VERSION ""

NS_ :

BS_:

BU_: VESC1 VESC2 VESC3 VESC4 VESC5 VESC6 VESC7 VESC8 Main_ECU

BO_ 3221225472 VECTOR__INDEPENDENT_SIG_MSG: 0 Vector__XXX
 SG_ TorqueValue : 7|8@0+ (1,0) [0|0] "V" Vector__XXX
 SG_ TorqueValue : 9|10@0+ (1,0) [0|0] "" Vector__XXX
 SG_ TorqueValue : 7|8@0+ (1,0) [0|0] "" Vector__XXX
 SG_ TorqueValue : 15|16@0+ (1,0) [0|0] "" Vector__XXX

BO_ 2147486728 VESC_Command_AbsHBrakeCurrent_V8: 8 Main_ECU
 SG_ Command_HBrakeCurrent_V8 : 7|32@0- (0.001,0) [-2147483.648|2147483.647] "mA"  VESC8

BO_ 2147486727 VESC_Command_AbsHBrakeCurrent_V7: 8 Main_ECU
 SG_ Command_HBrakeCurrent_V7 : 7|32@0- (0.001,0) [-2147483.648|2147483.647] "mA"  VESC7

BO_ 2147486726 VESC_Command_AbsHBrakeCurrent_V6: 8 Main_ECU
 SG_ Command_HBrakeCurrent_V6 : 7|32@0- (0.001,0) [-2147483.648|2147483.647] "mA"  VESC6

BO_ 2147486725 VESC_Command_AbsHBrakeCurrent_V5: 8 Main_ECU
 SG_ Command_HBrakeCurrent_V5 : 7|32@0- (0.001,0) [-2147483.648|2147483.647] "mA"  VESC5

BO_ 2147486724 VESC_Command_AbsHBrakeCurrent_V4: 8 Main_ECU
 SG_ Command_HBrakeCurrent_V4 : 7|32@0- (0.001,0) [-2147483.648|2147483.647] "mA"  VESC4

BO_ 2147486723 VESC_Command_AbsHBrakeCurrent_V3: 8 Main_ECU
 SG_ Command_HBrakeCurrent_V3 : 7|32@0- (0.001,0) [-2147483.648|2147483.647] "mA"  VESC3

BO_ 2147486722 VESC_Command_AbsHBrakeCurrent_V2: 8 Main_ECU
 SG_ Command_HBrakeCurrent_V2 : 7|32@0- (0.001,0) [-2147483.648|2147483.647] "mA"  VESC2

BO_ 2147486721 VESC_Command_AbsHBrakeCurrent_V1: 8 Main_ECU
 SG_ Command_HBrakeCurrent_V1 : 7|32@0- (0.001,0) [-2147483.648|2147483.647] "mA"  VESC1

BO_ 2147486984 VESC_Command_RelHBrakeCurrent_V8: 8 Main_ECU
 SG_ Command_RelativeHBrakeCurrent_V8 : 7|32@0- (0.001,0) [-100|100] "%"  VESC8

BO_ 2147486983 VESC_Command_RelHBrakeCurrent_V7: 8 Main_ECU
 SG_ Command_RelativeHBrakeCurrent_V7 : 7|32@0- (0.001,0) [-100|100] "%"  VESC7

BO_ 2147486982 VESC_Command_RelHBrakeCurrent_V6: 8 Main_ECU
 SG_ Command_RelativeHBrakeCurrent_V6 : 7|32@0- (0.001,0) [-100|100] "%"  VESC6

BO_ 2147486981 VESC_Command_RelHBrakeCurrent_V5: 8 Main_ECU
 SG_ Command_RelativeHBrakeCurrent_V5 : 7|32@0- (0.001,0) [-100|100] "%"  VESC5

BO_ 2147486980 VESC_Command_RelHBrakeCurrent_V4: 8 Main_ECU
 SG_ Command_RelativeHBrakeCurrent_V4 : 7|32@0- (0.001,0) [-100|100] "%"  VESC4

BO_ 2147486979 VESC_Command_RelHBrakeCurrent_V3: 8 Main_ECU
 SG_ Command_RelativeHBrakeCurrent_V3 : 7|32@0- (0.001,0) [-100|100] "%"  VESC3

BO_ 2147486978 VESC_Command_RelHBrakeCurrent_V2: 8 Main_ECU
 SG_ Command_RelativeHBrakeCurrent_V2 : 7|32@0- (0.001,0) [-100|100] "%"  VESC2

BO_ 2147486977 VESC_Command_RelHBrakeCurrent_V1: 8 Main_ECU
 SG_ Command_RelativeHBrakeCurrent_V1 : 7|32@0- (0.001,0) [-100|100] "%"  VESC1

BO_ 2147489281 VESC_Set_CurrentLimitPerm_V1: 8 Main_ECU
 SG_ Setting_CurrentLimitMin_V1 : 7|32@0- (0.001,0) [-2147483.648|2147483.647] ""  VESC1
 SG_ Setting_CurrentLimitMax_V1 : 39|32@0- (0.001,0) [-2147483.648|2147483.647] ""  VESC1

BO_ 2147489025 VESC_Set_CurrentLimitTemp_V1: 8 Main_ECU
 SG_ Setting_CurrentLimitMin_V1 : 7|32@0- (0.001,0) [-2147483.648|2147483.647] ""  VESC1
 SG_ Setting_CurrentLimitMax_V1 : 39|32@0- (0.001,0) [-2147483.648|2147483.647] ""  VESC1

BO_ 2147486465 VESC_Command_RelBrakeCurrent_V1: 4 Main_ECU
 SG_ Command_RelativeBrakeCurrent_V1 : 7|32@0- (0.001,0) [-100|100] "%"  VESC1

BO_ 2147486209 VESC_Command_RelCurrent_V1: 4 Main_ECU
 SG_ Command_RelativeCurrent_V1 : 7|32@0- (0.001,0) [-100|100] "%"  VESC1

BO_ 2147484673 VESC_Command_POS_V1: 4 Main_ECU
 SG_ Command_POS_V1 : 7|32@0- (1,0) [-2147483648|2147483647] "RPM"  VESC1

BO_ 2147484161 VESC_Command_AbsBrakeCurrent_V1: 4 Main_ECU
 SG_ Command_BrakeCurrent_V1 : 7|32@0- (0.001,0) [-2147483.648|2147483.647] "mA"  VESC1

BO_ 2147483905 VESC_Command_AbsCurrent_V1: 4 Main_ECU
 SG_ Command_Current_V1 : 7|32@0- (0.001,0) [-2147483.648|2147483.647] "mA"  VESC1

BO_ 2147484417 VESC_Command_RPM_V1: 4 Main_ECU
 SG_ Command_RPM_V1 : 7|32@0- (1,0) [-2147483648|2147483647] "RPM"  VESC1

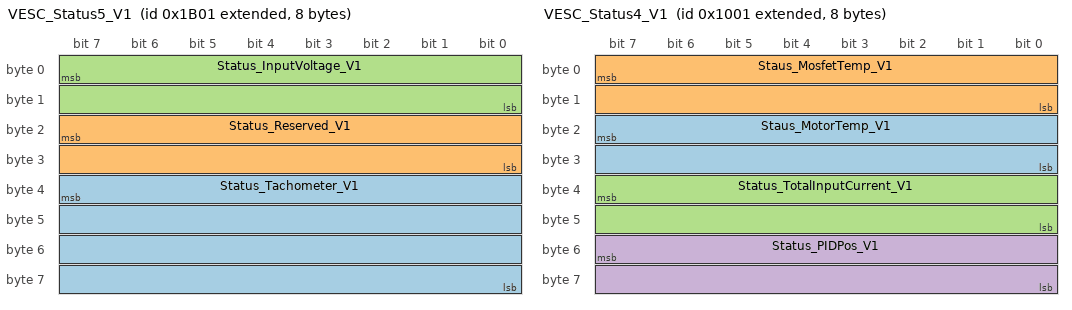
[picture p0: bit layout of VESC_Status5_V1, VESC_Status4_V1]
BO_ 2147490561 VESC_Status5_V1: 8 VESC1
 SG_ Status_Tachometer_V1 : 39|32@0- (1,0) [0|0] "RPM"  Main_ECU
 SG_ Status_Reserved_V1 : 23|16@0- (1,0) [0|0] ""  Main_ECU
 SG_ Status_InputVoltage_V1 : 7|16@0- (0.1,0) [0|0] ""  Main_ECU

BO_ 2147487745 VESC_Status4_V1: 8 VESC1
 SG_ Staus_MotorTemp_V1 : 23|16@0- (0.1,0) [-3276.8|3276.7] "°C"  Main_ECU
 SG_ Staus_MosfetTemp_V1 : 7|16@0- (0.1,0) [-3276.8|3276.7] "°C"  Main_ECU
 SG_ Status_TotalInputCurrent_V1 : 39|16@0- (0.1,0) [-3276.8|3276.7] "A"  Main_ECU
 SG_ Status_PIDPos_V1 : 55|16@0- (0.02,0) [-655.36|655.34] ""  Main_ECU

BO_ 2147487489 VESC_Status3_V1: 8 VESC1
 SG_ Status_WattHoursCharged_V1 : 39|32@0- (1e-05,0) [-21474.83648|21474.83647] "Wh"  Main_ECU
 SG_ Status_WattHours_V1 : 7|32@0- (1e-05,0) [-21474.83648|21474.83647] "Wh"  Main_ECU

BO_ 2147487233 VESC_Status2_V1: 8 VESC1
 SG_ Status_AmpHoursCharged_V1 : 39|32@0- (1e-05,0) [-21474.83648|21474.83647] "Ah"  Main_ECU
 SG_ Status_AmpHours_V1 : 7|32@0- (1e-05,0) [-21474.83648|21474.83647] "Ah"  Main_ECU

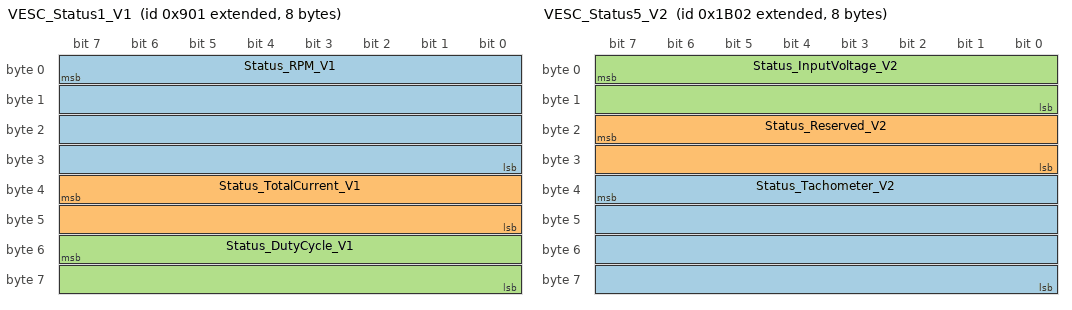
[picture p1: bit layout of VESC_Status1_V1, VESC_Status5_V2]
BO_ 2147485953 VESC_Status1_V1: 8 VESC1
 SG_ Status_RPM_V1 : 7|32@0- (1,0) [-2147483648|2147483647] "RPM"  Main_ECU
 SG_ Status_TotalCurrent_V1 : 39|16@0- (0.1,0) [-3276.8|3276.7] "A"  Main_ECU
 SG_ Status_DutyCycle_V1 : 55|16@0- (0.1,0) [-100|100] "%"  Main_ECU

BO_ 2147483649 VESC_Command_DutyCycle_V1: 4 Main_ECU
 SG_ Command_DutyCycle_V1 : 7|32@0- (0.001,0) [-100|100] "%"  VESC1

BO_ 2147489282 VESC_Set_CurrentLimitPerm_V2: 8 Main_ECU
 SG_ Setting_CurrentLimitMin_V2 : 7|32@0- (0.001,0) [-2147483.648|2147483.647] ""  VESC2
 SG_ Setting_CurrentLimitMax_V2 : 39|32@0- (0.001,0) [-2147483.648|2147483.647] ""  VESC2

BO_ 2147489026 VESC_Set_CurrentLimitTemp_V2: 8 Main_ECU
 SG_ Setting_CurrentLimitMin_V2 : 7|32@0- (0.001,0) [-2147483.648|2147483.647] ""  VESC2
 SG_ Setting_CurrentLimitMax_V2 : 39|32@0- (0.001,0) [-2147483.648|2147483.647] ""  VESC2

BO_ 2147486466 VESC_Command_RelBrakeCurrent_V2: 4 Main_ECU
 SG_ Command_RelativeBrakeCurrent_V2 : 7|32@0- (0.001,0) [-100|100] "%"  VESC2

BO_ 2147486210 VESC_Command_RelCurrent_V2: 4 Main_ECU
 SG_ Command_RelativeCurrent_V2 : 7|32@0- (0.001,0) [-100|100] "%"  VESC2

BO_ 2147484674 VESC_Command_POS_V2: 4 Main_ECU
 SG_ Command_POS_V2 : 7|32@0- (1,0) [-2147483648|2147483647] "RPM"  VESC2

BO_ 2147484162 VESC_Command_AbsBrakeCurrent_V2: 4 Main_ECU
 SG_ Command_BrakeCurrent_V2 : 7|32@0- (0.001,0) [-2147483.648|2147483.647] "mA"  VESC2

BO_ 2147483906 VESC_Command_AbsCurrent_V2: 4 Main_ECU
 SG_ Command_Current_V2 : 7|32@0- (0.001,0) [-2147483.648|2147483.647] "mA"  VESC2

BO_ 2147484418 VESC_Command_RPM_V2: 4 Main_ECU
 SG_ Command_RPM_V2 : 7|32@0- (1,0) [-2147483648|2147483647] "RPM"  VESC2

BO_ 2147490562 VESC_Status5_V2: 8 VESC2
 SG_ Status_Tachometer_V2 : 39|32@0- (1,0) [0|0] "RPM"  Main_ECU
 SG_ Status_Reserved_V2 : 23|16@0- (1,0) [0|0] ""  Main_ECU
 SG_ Status_InputVoltage_V2 : 7|16@0- (0.1,0) [0|0] ""  Main_ECU

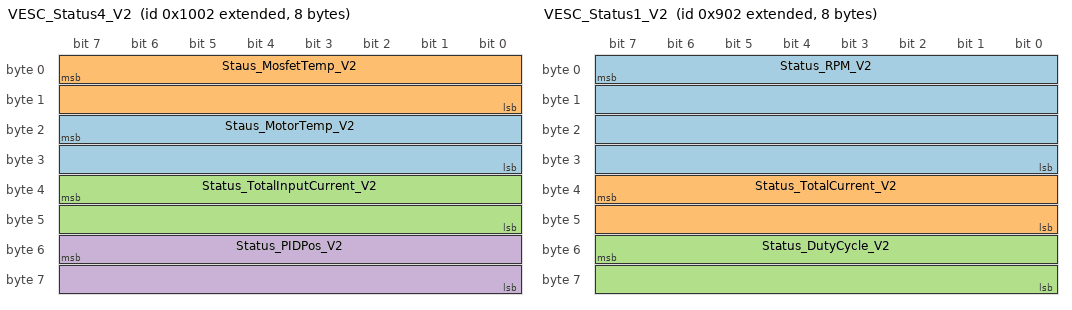
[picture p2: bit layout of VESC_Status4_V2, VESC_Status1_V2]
BO_ 2147487746 VESC_Status4_V2: 8 VESC2
 SG_ Staus_MotorTemp_V2 : 23|16@0- (0.1,0) [-3276.8|3276.7] "°C"  Main_ECU
 SG_ Staus_MosfetTemp_V2 : 7|16@0- (0.1,0) [-3276.8|3276.7] "°C"  Main_ECU
 SG_ Status_TotalInputCurrent_V2 : 39|16@0- (0.1,0) [-3276.8|3276.7] "A"  Main_ECU
 SG_ Status_PIDPos_V2 : 55|16@0- (0.02,0) [-655.36|655.34] ""  Main_ECU

BO_ 2147487490 VESC_Status3_V2: 8 VESC2
 SG_ Status_WattHoursCharged_V2 : 39|32@0- (1e-05,0) [-21474.83648|21474.83647] "Wh"  Main_ECU
 SG_ Status_WattHours_V2 : 7|32@0- (1e-05,0) [-21474.83648|21474.83647] "Wh"  Main_ECU

BO_ 2147487234 VESC_Status2_V2: 8 VESC2
 SG_ Status_AmpHoursCharged_V2 : 39|32@0- (1e-05,0) [-21474.83648|21474.83647] "Ah"  Main_ECU
 SG_ Status_AmpHours_V2 : 7|32@0- (1e-05,0) [-21474.83648|21474.83647] "Ah"  Main_ECU

BO_ 2147485954 VESC_Status1_V2: 8 VESC2
 SG_ Status_RPM_V2 : 7|32@0- (1,0) [-2147483648|2147483647] "RPM"  Main_ECU
 SG_ Status_TotalCurrent_V2 : 39|16@0- (0.1,0) [-3276.8|3276.7] "A"  Main_ECU
 SG_ Status_DutyCycle_V2 : 55|16@0- (0.1,0) [-100|100] "%"  Main_ECU

BO_ 2147483650 VESC_Command_DutyCycle_V2: 4 Main_ECU
 SG_ Command_DutyCycle_V2 : 7|32@0- (0.001,0) [-100|100] "%"  VESC2

BO_ 2147489283 VESC_Set_CurrentLimitPerm_V3: 8 Main_ECU
 SG_ Setting_CurrentLimitMin_V3 : 7|32@0- (0.001,0) [-2147483.648|2147483.647] ""  VESC3
 SG_ Setting_CurrentLimitMax_V3 : 39|32@0- (0.001,0) [-2147483.648|2147483.647] ""  VESC3

BO_ 2147489027 VESC_Set_CurrentLimitTemp_V3: 8 Main_ECU
 SG_ Setting_CurrentLimitMin_V3 : 7|32@0- (0.001,0) [-2147483.648|2147483.647] ""  VESC3
 SG_ Setting_CurrentLimitMax_V3 : 39|32@0- (0.001,0) [-2147483.648|2147483.647] ""  VESC3

BO_ 2147486467 VESC_Command_RelBrakeCurrent_V3: 4 Main_ECU
 SG_ Command_RelativeBrakeCurrent_V3 : 7|32@0- (0.001,0) [-100|100] "%"  VESC3

BO_ 2147486211 VESC_Command_RelCurrent_V3: 4 Main_ECU
 SG_ Command_RelativeCurrent_V3 : 7|32@0- (0.001,0) [-100|100] "%"  VESC3

BO_ 2147484675 VESC_Command_POS_V3: 4 Main_ECU
 SG_ Command_POS_V3 : 7|32@0- (1,0) [-2147483648|2147483647] "RPM"  VESC3

BO_ 2147484163 VESC_Command_AbsBrakeCurrent_V3: 4 Main_ECU
 SG_ Command_BrakeCurrent_V3 : 7|32@0- (0.001,0) [-2147483.648|2147483.647] "mA"  VESC3

BO_ 2147483907 VESC_Command_AbsCurrent_V3: 4 Main_ECU
 SG_ Command_Current_V3 : 7|32@0- (0.001,0) [-2147483.648|2147483.647] "mA"  VESC3

BO_ 2147484419 VESC_Command_RPM_V3: 4 Main_ECU
 SG_ Command_RPM_V3 : 7|32@0- (1,0) [-2147483648|2147483647] "RPM"  VESC3

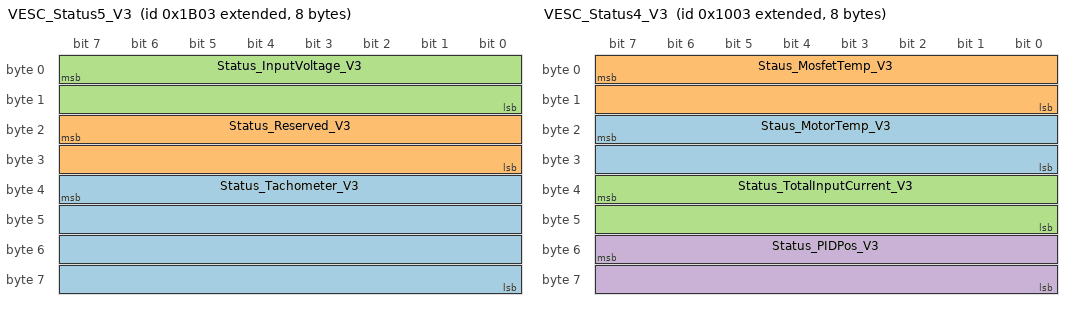
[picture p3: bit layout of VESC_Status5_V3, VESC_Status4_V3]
BO_ 2147490563 VESC_Status5_V3: 8 VESC3
 SG_ Status_Tachometer_V3 : 39|32@0- (1,0) [0|0] "RPM"  Main_ECU
 SG_ Status_Reserved_V3 : 23|16@0- (1,0) [0|0] ""  Main_ECU
 SG_ Status_InputVoltage_V3 : 7|16@0- (0.1,0) [0|0] ""  Main_ECU

BO_ 2147487747 VESC_Status4_V3: 8 VESC3
 SG_ Staus_MotorTemp_V3 : 23|16@0- (0.1,0) [-3276.8|3276.7] "°C"  Main_ECU
 SG_ Staus_MosfetTemp_V3 : 7|16@0- (0.1,0) [-3276.8|3276.7] "°C"  Main_ECU
 SG_ Status_TotalInputCurrent_V3 : 39|16@0- (0.1,0) [-3276.8|3276.7] "A"  Main_ECU
 SG_ Status_PIDPos_V3 : 55|16@0- (0.02,0) [-655.36|655.34] ""  Main_ECU

BO_ 2147487491 VESC_Status3_V3: 8 VESC3
 SG_ Status_WattHoursCharged_V3 : 39|32@0- (1e-05,0) [-21474.83648|21474.83647] "Wh"  Main_ECU
 SG_ Status_WattHours_V3 : 7|32@0- (1e-05,0) [-21474.83648|21474.83647] "Wh"  Main_ECU

BO_ 2147487235 VESC_Status2_V3: 8 VESC3
 SG_ Status_AmpHoursCharged_V3 : 39|32@0- (1e-05,0) [-21474.83648|21474.83647] "Ah"  Main_ECU
 SG_ Status_AmpHours_V3 : 7|32@0- (1e-05,0) [-21474.83648|21474.83647] "Ah"  Main_ECU

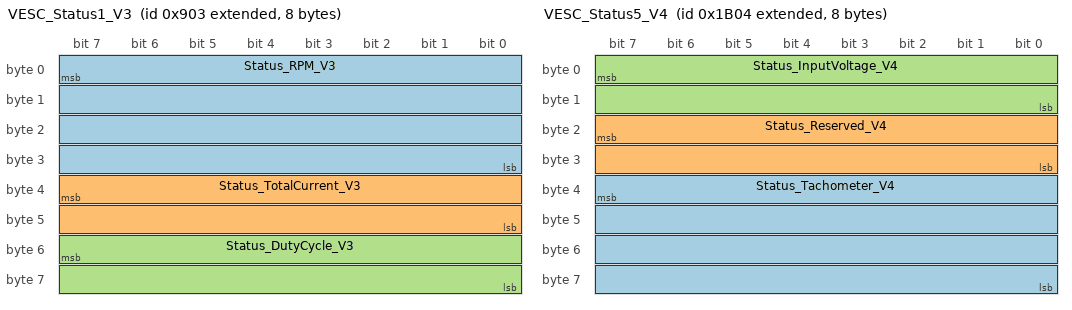
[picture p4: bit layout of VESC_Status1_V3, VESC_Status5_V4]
BO_ 2147485955 VESC_Status1_V3: 8 VESC3
 SG_ Status_RPM_V3 : 7|32@0- (1,0) [-2147483648|2147483647] "RPM"  Main_ECU
 SG_ Status_TotalCurrent_V3 : 39|16@0- (0.1,0) [-3276.8|3276.7] "A"  Main_ECU
 SG_ Status_DutyCycle_V3 : 55|16@0- (0.1,0) [-100|100] "%"  Main_ECU

BO_ 2147483651 VESC_Command_DutyCycle_V3: 4 Main_ECU
 SG_ Command_DutyCycle_V3 : 7|32@0- (0.001,0) [-100|100] "%"  VESC3

BO_ 2147489284 VESC_Set_CurrentLimitPerm_V4: 8 Main_ECU
 SG_ Setting_CurrentLimitMin_V4 : 7|32@0- (0.001,0) [-2147483.648|2147483.647] ""  VESC4
 SG_ Setting_CurrentLimitMax_V4 : 39|32@0- (0.001,0) [-2147483.648|2147483.647] ""  VESC4

BO_ 2147489028 VESC_Set_CurrentLimitTemp_V4: 8 Main_ECU
 SG_ Setting_CurrentLimitMin_V4 : 7|32@0- (0.001,0) [-2147483.648|2147483.647] ""  VESC4
 SG_ Setting_CurrentLimitMax_V4 : 39|32@0- (0.001,0) [-2147483.648|2147483.647] ""  VESC4

BO_ 2147486468 VESC_Command_RelBrakeCurrent_V4: 4 Main_ECU
 SG_ Command_RelativeBrakeCurrent_V4 : 7|32@0- (0.001,0) [-100|100] "%"  VESC4

BO_ 2147486212 VESC_Command_RelCurrent_V4: 4 Main_ECU
 SG_ Command_RelativeCurrent_V4 : 7|32@0- (0.001,0) [-100|100] "%"  VESC4

BO_ 2147484676 VESC_Command_POS_V4: 4 Main_ECU
 SG_ Command_POS_V4 : 7|32@0- (1,0) [-2147483648|2147483647] "RPM"  VESC4

BO_ 2147484164 VESC_Command_AbsBrakeCurrent_V4: 4 Main_ECU
 SG_ Command_BrakeCurrent_V4 : 7|32@0- (0.001,0) [-2147483.648|2147483.647] "mA"  VESC4

BO_ 2147483908 VESC_Command_AbsCurrent_V4: 4 Main_ECU
 SG_ Command_Current_V4 : 7|32@0- (0.001,0) [-2147483.648|2147483.647] "mA"  VESC4

BO_ 2147484420 VESC_Command_RPM_V4: 4 Main_ECU
 SG_ Command_RPM_V4 : 7|32@0- (1,0) [-2147483648|2147483647] "RPM"  VESC4

BO_ 2147490564 VESC_Status5_V4: 8 VESC4
 SG_ Status_Tachometer_V4 : 39|32@0- (1,0) [0|0] "RPM"  Main_ECU
 SG_ Status_Reserved_V4 : 23|16@0- (1,0) [0|0] ""  Main_ECU
 SG_ Status_InputVoltage_V4 : 7|16@0- (0.1,0) [0|0] ""  Main_ECU

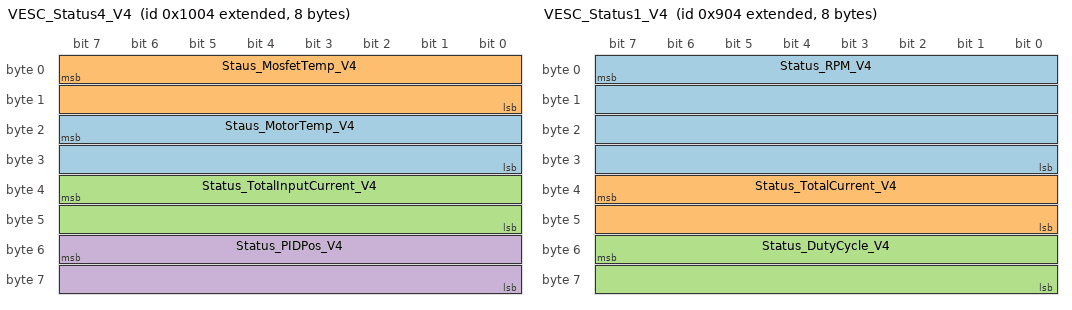
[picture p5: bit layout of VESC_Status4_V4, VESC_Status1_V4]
BO_ 2147487748 VESC_Status4_V4: 8 VESC4
 SG_ Staus_MotorTemp_V4 : 23|16@0- (0.1,0) [-3276.8|3276.7] "°C"  Main_ECU
 SG_ Staus_MosfetTemp_V4 : 7|16@0- (0.1,0) [-3276.8|3276.7] "°C"  Main_ECU
 SG_ Status_TotalInputCurrent_V4 : 39|16@0- (0.1,0) [-3276.8|3276.7] "A"  Main_ECU
 SG_ Status_PIDPos_V4 : 55|16@0- (0.02,0) [-655.36|655.34] ""  Main_ECU

BO_ 2147487492 VESC_Status3_V4: 8 VESC4
 SG_ Status_WattHoursCharged_V4 : 39|32@0- (1e-05,0) [-21474.83648|21474.83647] "Wh"  Main_ECU
 SG_ Status_WattHours_V4 : 7|32@0- (1e-05,0) [-21474.83648|21474.83647] "Wh"  Main_ECU

BO_ 2147487236 VESC_Status2_V4: 8 VESC4
 SG_ Status_AmpHoursCharged_V4 : 39|32@0- (1e-05,0) [-21474.83648|21474.83647] "Ah"  Main_ECU
 SG_ Status_AmpHours_V4 : 7|32@0- (1e-05,0) [-21474.83648|21474.83647] "Ah"  Main_ECU

BO_ 2147485956 VESC_Status1_V4: 8 VESC4
 SG_ Status_RPM_V4 : 7|32@0- (1,0) [-2147483648|2147483647] "RPM"  Main_ECU
 SG_ Status_TotalCurrent_V4 : 39|16@0- (0.1,0) [-3276.8|3276.7] "A"  Main_ECU
 SG_ Status_DutyCycle_V4 : 55|16@0- (0.1,0) [-100|100] "%"  Main_ECU

BO_ 2147483652 VESC_Command_DutyCycle_V4: 4 Main_ECU
 SG_ Command_DutyCycle_V4 : 7|32@0- (0.001,0) [-100|100] "%"  VESC4

BO_ 2147489285 VESC_Set_CurrentLimitPerm_V5: 8 Main_ECU
 SG_ Setting_CurrentLimitMin_V5 : 7|32@0- (0.001,0) [-2147483.648|2147483.647] ""  VESC5
 SG_ Setting_CurrentLimitMax_V5 : 39|32@0- (0.001,0) [-2147483.648|2147483.647] ""  VESC5

BO_ 2147489029 VESC_Set_CurrentLimitTemp_V5: 8 Main_ECU
 SG_ Setting_CurrentLimitMin_V5 : 7|32@0- (0.001,0) [-2147483.648|2147483.647] ""  VESC5
 SG_ Setting_CurrentLimitMax_V5 : 39|32@0- (0.001,0) [-2147483.648|2147483.647] ""  VESC5

BO_ 2147486469 VESC_Command_RelBrakeCurrent_V5: 4 Main_ECU
 SG_ Command_RelativeBrakeCurrent_V5 : 7|32@0- (0.001,0) [-100|100] "%"  VESC5

BO_ 2147486213 VESC_Command_RelCurrent_V5: 4 Main_ECU
 SG_ Command_RelativeCurrent_V5 : 7|32@0- (0.001,0) [-100|100] "%"  VESC5

BO_ 2147484677 VESC_Command_POS_V5: 4 Main_ECU
 SG_ Command_POS_V5 : 7|32@0- (1,0) [-2147483648|2147483647] "RPM"  VESC5

BO_ 2147484165 VESC_Command_AbsBrakeCurrent_V5: 4 Main_ECU
 SG_ Command_BrakeCurrent_V5 : 7|32@0- (0.001,0) [-2147483.648|2147483.647] "mA"  VESC5

BO_ 2147483909 VESC_Command_AbsCurrent_V5: 4 Main_ECU
 SG_ Command_Current_V5 : 7|32@0- (0.001,0) [-2147483.648|2147483.647] "mA"  VESC5

BO_ 2147484421 VESC_Command_RPM_V5: 4 Main_ECU
 SG_ Command_RPM_V5 : 7|32@0- (1,0) [-2147483648|2147483647] "RPM"  VESC5

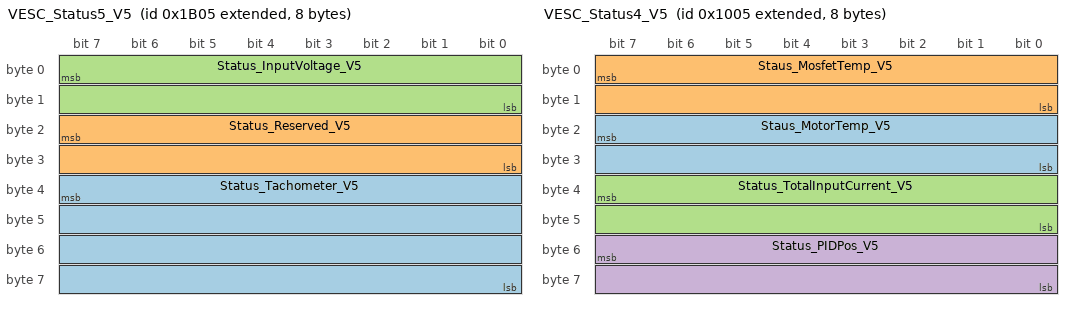
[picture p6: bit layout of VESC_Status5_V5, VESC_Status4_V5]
BO_ 2147490565 VESC_Status5_V5: 8 VESC5
 SG_ Status_Tachometer_V5 : 39|32@0- (1,0) [0|0] "RPM"  Main_ECU
 SG_ Status_Reserved_V5 : 23|16@0- (1,0) [0|0] ""  Main_ECU
 SG_ Status_InputVoltage_V5 : 7|16@0- (0.1,0) [0|0] ""  Main_ECU

BO_ 2147487749 VESC_Status4_V5: 8 VESC5
 SG_ Staus_MotorTemp_V5 : 23|16@0- (0.1,0) [-3276.8|3276.7] "°C"  Main_ECU
 SG_ Staus_MosfetTemp_V5 : 7|16@0- (0.1,0) [-3276.8|3276.7] "°C"  Main_ECU
 SG_ Status_TotalInputCurrent_V5 : 39|16@0- (0.1,0) [-3276.8|3276.7] "A"  Main_ECU
 SG_ Status_PIDPos_V5 : 55|16@0- (0.02,0) [-655.36|655.34] ""  Main_ECU

BO_ 2147487493 VESC_Status3_V5: 8 VESC5
 SG_ Status_WattHoursCharged_V5 : 39|32@0- (1e-05,0) [-21474.83648|21474.83647] "Wh"  Main_ECU
 SG_ Status_WattHours_V5 : 7|32@0- (1e-05,0) [-21474.83648|21474.83647] "Wh"  Main_ECU

BO_ 2147487237 VESC_Status2_V5: 8 VESC5
 SG_ Status_AmpHoursCharged_V5 : 39|32@0- (1e-05,0) [-21474.83648|21474.83647] "Ah"  Main_ECU
 SG_ Status_AmpHours_V5 : 7|32@0- (1e-05,0) [-21474.83648|21474.83647] "Ah"  Main_ECU

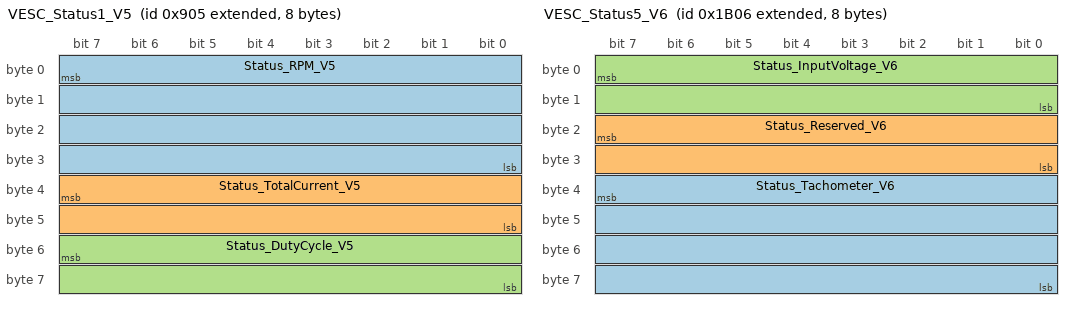
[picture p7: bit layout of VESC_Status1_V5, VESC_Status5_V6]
BO_ 2147485957 VESC_Status1_V5: 8 VESC5
 SG_ Status_RPM_V5 : 7|32@0- (1,0) [-2147483648|2147483647] "RPM"  Main_ECU
 SG_ Status_TotalCurrent_V5 : 39|16@0- (0.1,0) [-3276.8|3276.7] "A"  Main_ECU
 SG_ Status_DutyCycle_V5 : 55|16@0- (0.1,0) [-100|100] "%"  Main_ECU

BO_ 2147483653 VESC_Command_DutyCycle_V5: 4 Main_ECU
 SG_ Command_DutyCycle_V5 : 7|32@0- (0.001,0) [-100|100] "%"  VESC5

BO_ 2147489286 VESC_Set_CurrentLimitPerm_V6: 8 Main_ECU
 SG_ Setting_CurrentLimitMin_V6 : 7|32@0- (0.001,0) [-2147483.648|2147483.647] ""  VESC6
 SG_ Setting_CurrentLimitMax_V6 : 39|32@0- (0.001,0) [-2147483.648|2147483.647] ""  VESC6

BO_ 2147489030 VESC_Set_CurrentLimitTemp_V6: 8 Main_ECU
 SG_ Setting_CurrentLimitMin_V6 : 7|32@0- (0.001,0) [-2147483.648|2147483.647] ""  VESC6
 SG_ Setting_CurrentLimitMax_V6 : 39|32@0- (0.001,0) [-2147483.648|2147483.647] ""  VESC6

BO_ 2147486470 VESC_Command_RelBrakeCurrent_V6: 4 Main_ECU
 SG_ Command_RelativeBrakeCurrent_V6 : 7|32@0- (0.001,0) [-100|100] "%"  VESC6

BO_ 2147486214 VESC_Command_RelCurrent_V6: 4 Main_ECU
 SG_ Command_RelativeCurrent_V6 : 7|32@0- (0.001,0) [-100|100] "%"  VESC6

BO_ 2147484678 VESC_Command_POS_V6: 4 Main_ECU
 SG_ Command_POS_V6 : 7|32@0- (1,0) [-2147483648|2147483647] "RPM"  VESC6

BO_ 2147484166 VESC_Command_AbsBrakeCurrent_V6: 4 Main_ECU
 SG_ Command_BrakeCurrent_V6 : 7|32@0- (0.001,0) [-2147483.648|2147483.647] "mA"  VESC6

BO_ 2147483910 VESC_Command_AbsCurrent_V6: 4 Main_ECU
 SG_ Command_Current_V6 : 7|32@0- (0.001,0) [-2147483.648|2147483.647] "mA"  VESC6

BO_ 2147484422 VESC_Command_RPM_V6: 4 Main_ECU
 SG_ Command_RPM_V6 : 7|32@0- (1,0) [-2147483648|2147483647] "RPM"  VESC6

BO_ 2147490566 VESC_Status5_V6: 8 VESC6
 SG_ Status_Tachometer_V6 : 39|32@0- (1,0) [0|0] "RPM"  Main_ECU
 SG_ Status_Reserved_V6 : 23|16@0- (1,0) [0|0] ""  Main_ECU
 SG_ Status_InputVoltage_V6 : 7|16@0- (0.1,0) [0|0] ""  Main_ECU

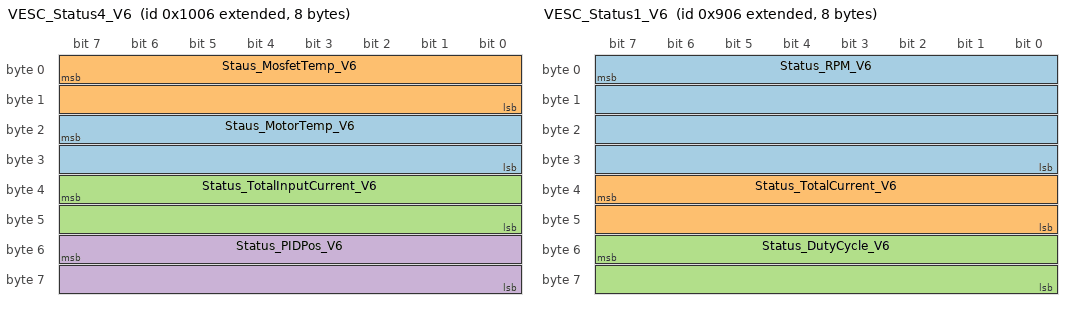
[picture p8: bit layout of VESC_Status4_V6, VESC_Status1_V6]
BO_ 2147487750 VESC_Status4_V6: 8 VESC6
 SG_ Staus_MotorTemp_V6 : 23|16@0- (0.1,0) [-3276.8|3276.7] "°C"  Main_ECU
 SG_ Staus_MosfetTemp_V6 : 7|16@0- (0.1,0) [-3276.8|3276.7] "°C"  Main_ECU
 SG_ Status_TotalInputCurrent_V6 : 39|16@0- (0.1,0) [-3276.8|3276.7] "A"  Main_ECU
 SG_ Status_PIDPos_V6 : 55|16@0- (0.02,0) [-655.36|655.34] ""  Main_ECU

BO_ 2147487494 VESC_Status3_V6: 8 VESC6
 SG_ Status_WattHoursCharged_V6 : 39|32@0- (1e-05,0) [-21474.83648|21474.83647] "Wh"  Main_ECU
 SG_ Status_WattHours_V6 : 7|32@0- (1e-05,0) [-21474.83648|21474.83647] "Wh"  Main_ECU

BO_ 2147487238 VESC_Status2_V6: 8 VESC6
 SG_ Status_AmpHoursCharged_V6 : 39|32@0- (1e-05,0) [-21474.83648|21474.83647] "Ah"  Main_ECU
 SG_ Status_AmpHours_V6 : 7|32@0- (1e-05,0) [-21474.83648|21474.83647] "Ah"  Main_ECU

BO_ 2147485958 VESC_Status1_V6: 8 VESC6
 SG_ Status_RPM_V6 : 7|32@0- (1,0) [-2147483648|2147483647] "RPM"  Main_ECU
 SG_ Status_TotalCurrent_V6 : 39|16@0- (0.1,0) [-3276.8|3276.7] "A"  Main_ECU
 SG_ Status_DutyCycle_V6 : 55|16@0- (0.1,0) [-100|100] "%"  Main_ECU

BO_ 2147483654 VESC_Command_DutyCycle_V6: 4 Main_ECU
 SG_ Command_DutyCycle_V6 : 7|32@0- (0.001,0) [-100|100] "%"  VESC6

BO_ 2147489287 VESC_Set_CurrentLimitPerm_V7: 8 Main_ECU
 SG_ Setting_CurrentLimitMin_V7 : 7|32@0- (0.001,0) [-2147483.648|2147483.647] ""  VESC7
 SG_ Setting_CurrentLimitMax_V7 : 39|32@0- (0.001,0) [-2147483.648|2147483.647] ""  VESC7

BO_ 2147489031 VESC_Set_CurrentLimitTemp_V7: 8 Main_ECU
 SG_ Setting_CurrentLimitMin_V7 : 7|32@0- (0.001,0) [-2147483.648|2147483.647] ""  VESC7
 SG_ Setting_CurrentLimitMax_V7 : 39|32@0- (0.001,0) [-2147483.648|2147483.647] ""  VESC7

BO_ 2147486471 VESC_Command_RelBrakeCurrent_V7: 4 Main_ECU
 SG_ Command_RelativeBrakeCurrent_V7 : 7|32@0- (0.001,0) [-100|100] "%"  VESC7

BO_ 2147486215 VESC_Command_RelCurrent_V7: 4 Main_ECU
 SG_ Command_RelativeCurrent_V7 : 7|32@0- (0.001,0) [-100|100] "%"  VESC7

BO_ 2147484679 VESC_Command_POS_V7: 4 Main_ECU
 SG_ Command_POS_V7 : 7|32@0- (1,0) [-2147483648|2147483647] "RPM"  VESC7

BO_ 2147484167 VESC_Command_AbsBrakeCurrent_V7: 4 Main_ECU
 SG_ Command_BrakeCurrent_V7 : 7|32@0- (0.001,0) [-2147483.648|2147483.647] "mA"  VESC7

BO_ 2147483911 VESC_Command_AbsCurrent_V7: 4 Main_ECU
 SG_ Command_Current_V7 : 7|32@0- (0.001,0) [-2147483.648|2147483.647] "mA"  VESC7

BO_ 2147484423 VESC_Command_RPM_V7: 4 Main_ECU
 SG_ Command_RPM_V7 : 7|32@0- (1,0) [-2147483648|2147483647] "RPM"  VESC7

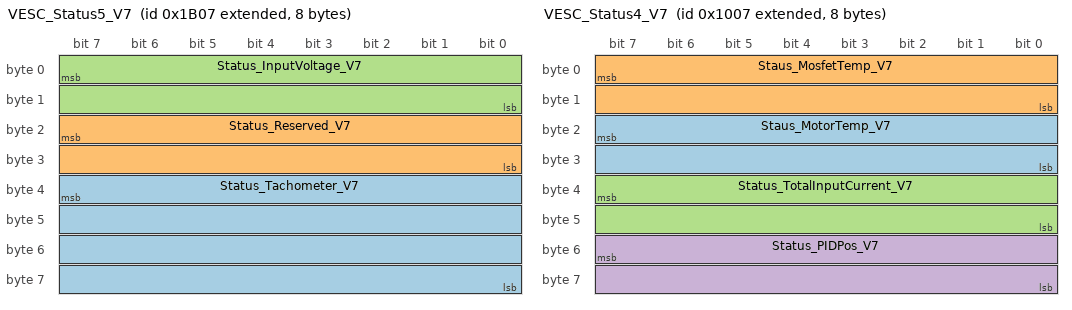
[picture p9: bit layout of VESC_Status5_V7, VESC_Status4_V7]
BO_ 2147490567 VESC_Status5_V7: 8 VESC7
 SG_ Status_Tachometer_V7 : 39|32@0- (1,0) [0|0] "RPM"  Main_ECU
 SG_ Status_Reserved_V7 : 23|16@0- (1,0) [0|0] ""  Main_ECU
 SG_ Status_InputVoltage_V7 : 7|16@0- (0.1,0) [0|0] ""  Main_ECU

BO_ 2147487751 VESC_Status4_V7: 8 VESC7
 SG_ Staus_MotorTemp_V7 : 23|16@0- (0.1,0) [-3276.8|3276.7] "°C"  Main_ECU
 SG_ Staus_MosfetTemp_V7 : 7|16@0- (0.1,0) [-3276.8|3276.7] "°C"  Main_ECU
 SG_ Status_TotalInputCurrent_V7 : 39|16@0- (0.1,0) [-3276.8|3276.7] "A"  Main_ECU
 SG_ Status_PIDPos_V7 : 55|16@0- (0.02,0) [-655.36|655.34] ""  Main_ECU

BO_ 2147487495 VESC_Status3_V7: 8 VESC7
 SG_ Status_WattHoursCharged_V7 : 39|32@0- (1e-05,0) [-21474.83648|21474.83647] "Wh"  Main_ECU
 SG_ Status_WattHours_V7 : 7|32@0- (1e-05,0) [-21474.83648|21474.83647] "Wh"  Main_ECU

BO_ 2147487239 VESC_Status2_V7: 8 VESC7
 SG_ Status_AmpHoursCharged_V7 : 39|32@0- (1e-05,0) [-21474.83648|21474.83647] "Ah"  Main_ECU
 SG_ Status_AmpHours_V7 : 7|32@0- (1e-05,0) [-21474.83648|21474.83647] "Ah"  Main_ECU

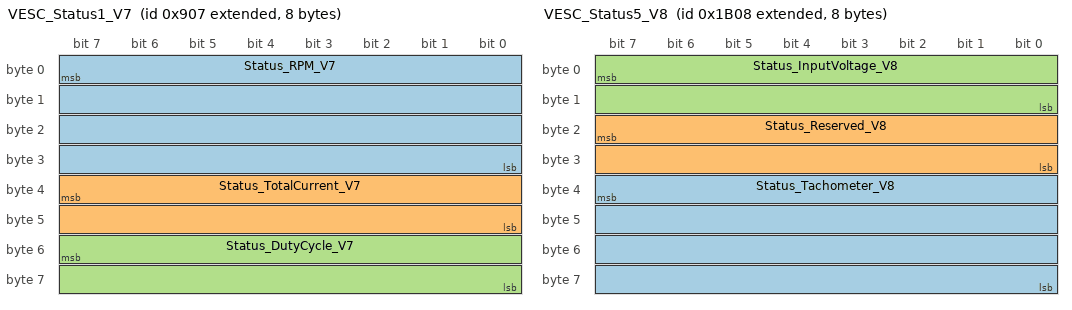
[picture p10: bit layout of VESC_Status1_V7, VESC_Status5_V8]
BO_ 2147485959 VESC_Status1_V7: 8 VESC7
 SG_ Status_RPM_V7 : 7|32@0- (1,0) [-2147483648|2147483647] "RPM"  Main_ECU
 SG_ Status_TotalCurrent_V7 : 39|16@0- (0.1,0) [-3276.8|3276.7] "A"  Main_ECU
 SG_ Status_DutyCycle_V7 : 55|16@0- (0.1,0) [-100|100] "%"  Main_ECU

BO_ 2147483655 VESC_Command_DutyCycle_V7: 4 Main_ECU
 SG_ Command_DutyCycle_V7 : 7|32@0- (0.001,0) [-100|100] "%"  VESC7

BO_ 2147489288 VESC_Set_CurrentLimitPerm_V8: 8 Main_ECU
 SG_ Setting_CurrentLimitMin_V8 : 7|32@0- (0.001,0) [-2147483.648|2147483.647] ""  VESC8
 SG_ Setting_CurrentLimitMax_V8 : 39|32@0- (0.001,0) [-2147483.648|2147483.647] ""  VESC8

BO_ 2147489032 VESC_Set_CurrentLimitTemp_V8: 8 Main_ECU
 SG_ Setting_CurrentLimitMin_V8 : 7|32@0- (0.001,0) [-2147483.648|2147483.647] ""  VESC8
 SG_ Setting_CurrentLimitMax_V8 : 39|32@0- (0.001,0) [-2147483.648|2147483.647] ""  VESC8

BO_ 2147486472 VESC_Command_RelBrakeCurrent_V8: 4 Main_ECU
 SG_ Command_RelativeBrakeCurrent_V8 : 7|32@0- (0.001,0) [-100|100] "%"  VESC8

BO_ 2147486216 VESC_Command_RelCurrent_V8: 4 Main_ECU
 SG_ Command_RelativeCurrent_V8 : 7|32@0- (0.001,0) [-100|100] "%"  VESC8

BO_ 2147484680 VESC_Command_POS_V8: 4 Main_ECU
 SG_ Command_POS_V8 : 7|32@0- (1,0) [-2147483648|2147483647] "RPM"  VESC8

BO_ 2147484168 VESC_Command_AbsBrakeCurrent_V8: 4 Main_ECU
 SG_ Command_BrakeCurrent_V8 : 7|32@0- (0.001,0) [-2147483.648|2147483.647] "mA"  VESC8

BO_ 2147483912 VESC_Command_AbsCurrent_V8: 4 Main_ECU
 SG_ Command_Current_V8 : 7|32@0- (0.001,0) [-2147483.648|2147483.647] "mA"  VESC8

BO_ 2147484424 VESC_Command_RPM_V8: 4 Main_ECU
 SG_ Command_RPM_V8 : 7|32@0- (1,0) [-2147483648|2147483647] "RPM"  VESC8

BO_ 2147490568 VESC_Status5_V8: 8 VESC8
 SG_ Status_Tachometer_V8 : 39|32@0- (1,0) [0|0] "RPM"  Main_ECU
 SG_ Status_Reserved_V8 : 23|16@0- (1,0) [0|0] ""  Main_ECU
 SG_ Status_InputVoltage_V8 : 7|16@0- (0.1,0) [0|0] ""  Main_ECU

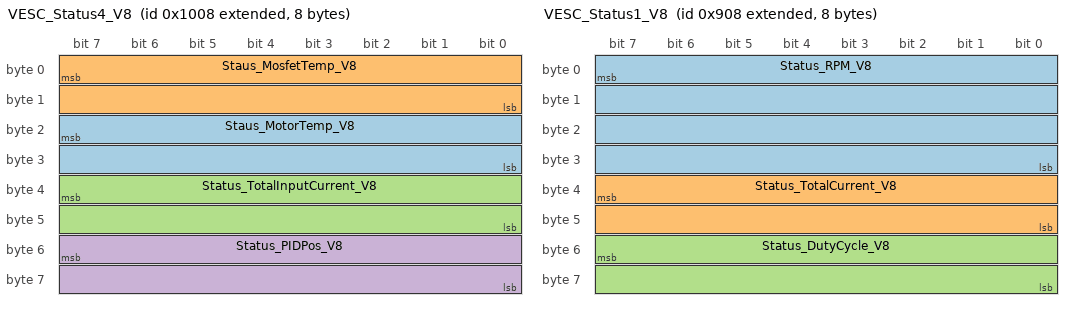
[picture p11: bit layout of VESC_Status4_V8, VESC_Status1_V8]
BO_ 2147487752 VESC_Status4_V8: 8 VESC8
 SG_ Staus_MotorTemp_V8 : 23|16@0- (0.1,0) [-3276.8|3276.7] "°C"  Main_ECU
 SG_ Staus_MosfetTemp_V8 : 7|16@0- (0.1,0) [-3276.8|3276.7] "°C"  Main_ECU
 SG_ Status_TotalInputCurrent_V8 : 39|16@0- (0.1,0) [-3276.8|3276.7] "A"  Main_ECU
 SG_ Status_PIDPos_V8 : 55|16@0- (0.02,0) [-655.36|655.34] ""  Main_ECU

BO_ 2147487496 VESC_Status3_V8: 8 VESC8
 SG_ Status_WattHoursCharged_V8 : 39|32@0- (1e-05,0) [-21474.83648|21474.83647] "Wh"  Main_ECU
 SG_ Status_WattHours_V8 : 7|32@0- (1e-05,0) [-21474.83648|21474.83647] "Wh"  Main_ECU

BO_ 2147487240 VESC_Status2_V8: 8 VESC8
 SG_ Status_AmpHoursCharged_V8 : 39|32@0- (1e-05,0) [-21474.83648|21474.83647] "Ah"  Main_ECU
 SG_ Status_AmpHours_V8 : 7|32@0- (1e-05,0) [-21474.83648|21474.83647] "Ah"  Main_ECU

BO_ 2147485960 VESC_Status1_V8: 8 VESC8
 SG_ Status_RPM_V8 : 7|32@0- (1,0) [-2147483648|2147483647] "RPM"  Main_ECU
 SG_ Status_TotalCurrent_V8 : 39|16@0- (0.1,0) [-3276.8|3276.7] "A"  Main_ECU
 SG_ Status_DutyCycle_V8 : 55|16@0- (0.1,0) [-100|100] "%"  Main_ECU

BO_ 2147483656 VESC_Command_DutyCycle_V8: 4 Main_ECU
 SG_ Command_DutyCycle_V8 : 7|32@0- (0.001,0) [-100|100] "%"  Main_ECU

BO_ 2147483673 TEENSY_Status: 2 Vector__XXX
 SG_ TorqueValue : 1|10@0+ (1,0) [0|0] "" Vector__XXX

BA_DEF_  "BusType" STRING ;
BA_DEF_DEF_  "BusType" "CAN";
